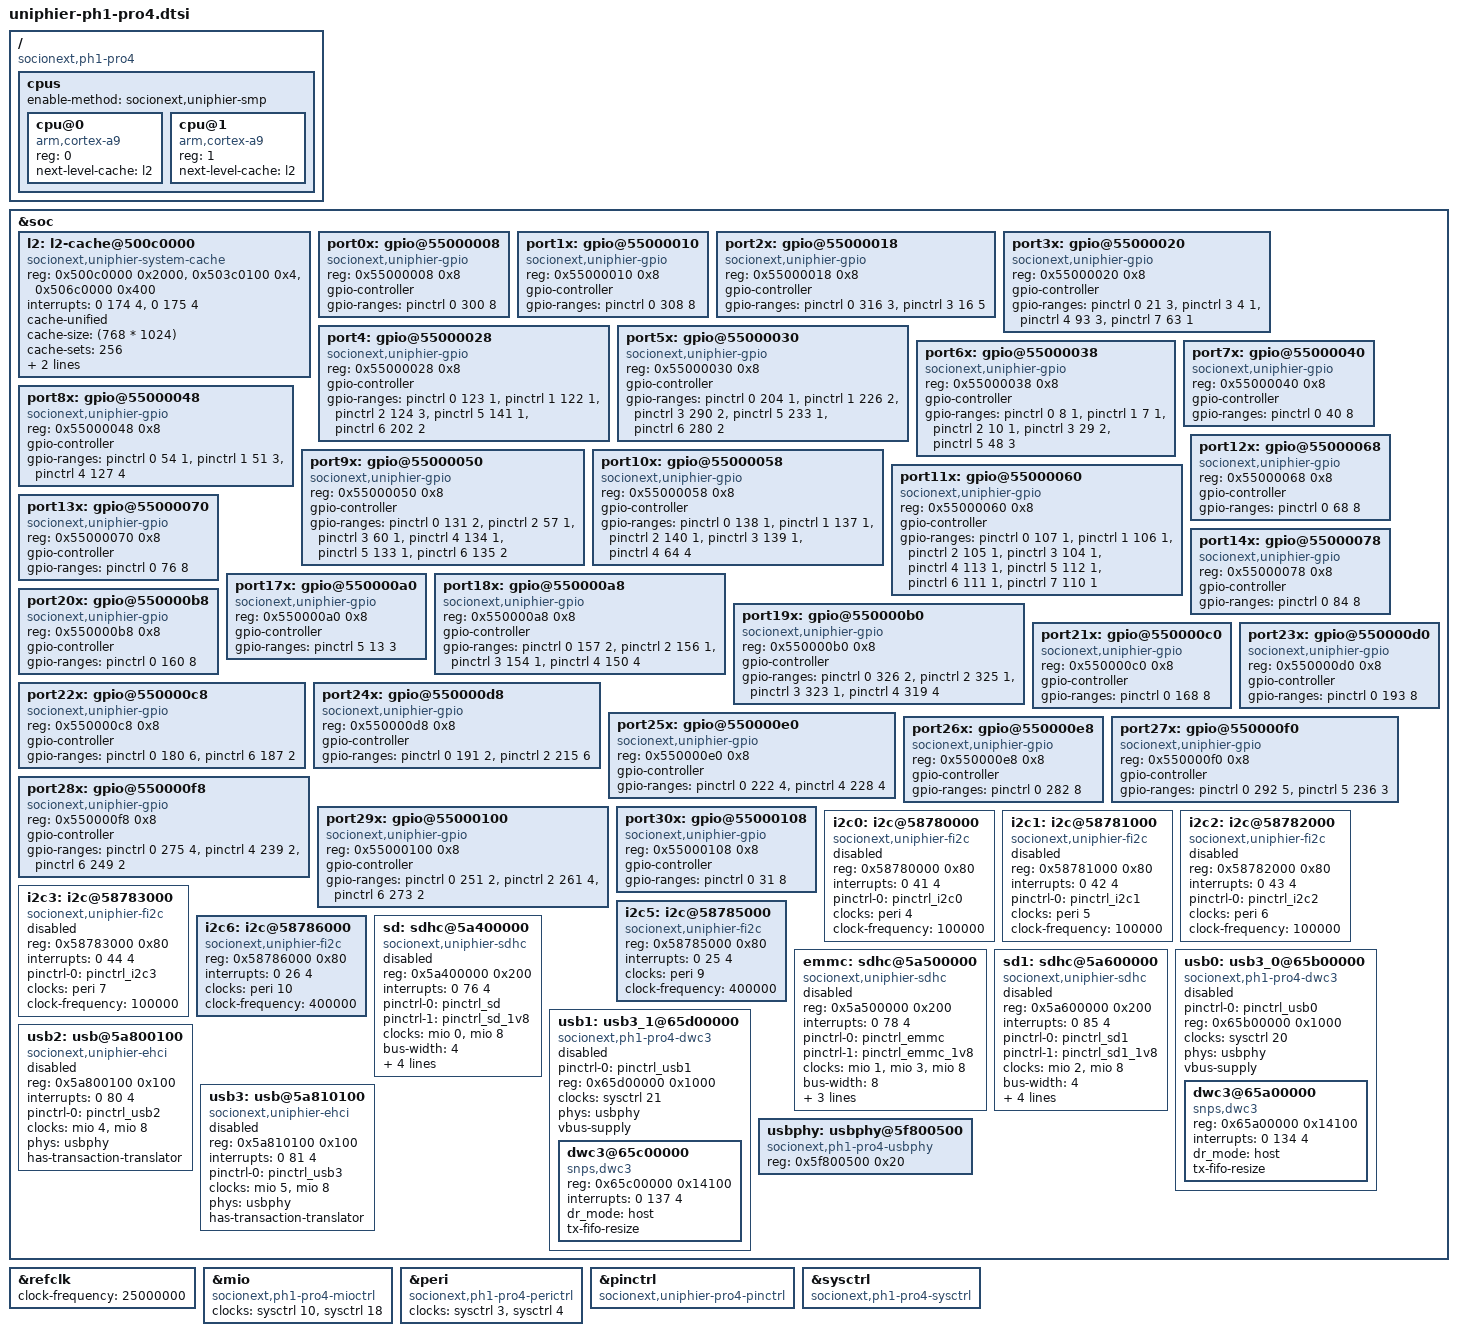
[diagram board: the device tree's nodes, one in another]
/*
 * Device Tree Source for UniPhier PH1-Pro4 SoC
 *
 * Copyright (C) 2015 Masahiro Yamada <yamada.masahiro@socionext.com>
 *
 * This file is dual-licensed: you can use it either under the terms
 * of the GPL or the X11 license, at your option. Note that this dual
 * licensing only applies to this file, and not this project as a
 * whole.
 *
 *  a) This file is free software; you can redistribute it and/or
 *     modify it under the terms of the GNU General Public License as
 *     published by the Free Software Foundation; either version 2 of the
 *     License, or (at your option) any later version.
 *
 *     This file is distributed in the hope that it will be useful,
 *     but WITHOUT ANY WARRANTY; without even the implied warranty of
 *     MERCHANTABILITY or FITNESS FOR A PARTICULAR PURPOSE.  See the
 *     GNU General Public License for more details.
 *
 * Or, alternatively,
 *
 *  b) Permission is hereby granted, free of charge, to any person
 *     obtaining a copy of this software and associated documentation
 *     files (the "Software"), to deal in the Software without
 *     restriction, including without limitation the rights to use,
 *     copy, modify, merge, publish, distribute, sublicense, and/or
 *     sell copies of the Software, and to permit persons to whom the
 *     Software is furnished to do so, subject to the following
 *     conditions:
 *
 *     The above copyright notice and this permission notice shall be
 *     included in all copies or substantial portions of the Software.
 *
 *     THE SOFTWARE IS PROVIDED "AS IS", WITHOUT WARRANTY OF ANY KIND,
 *     EXPRESS OR IMPLIED, INCLUDING BUT NOT LIMITED TO THE WARRANTIES
 *     OF MERCHANTABILITY, FITNESS FOR A PARTICULAR PURPOSE AND
 *     NONINFRINGEMENT. IN NO EVENT SHALL THE AUTHORS OR COPYRIGHT
 *     HOLDERS BE LIABLE FOR ANY CLAIM, DAMAGES OR OTHER LIABILITY,
 *     WHETHER IN AN ACTION OF CONTRACT, TORT OR OTHERWISE, ARISING
 *     FROM, OUT OF OR IN CONNECTION WITH THE SOFTWARE OR THE USE OR
 *     OTHER DEALINGS IN THE SOFTWARE.
 */

/include/ "uniphier-common32.dtsi"

/ {
	compatible = "socionext,ph1-pro4";

	cpus {
		#address-cells = <1>;
		#size-cells = <0>;
		enable-method = "socionext,uniphier-smp";

		cpu@0 {
			device_type = "cpu";
			compatible = "arm,cortex-a9";
			reg = <0>;
			next-level-cache = <&l2>;
		};

		cpu@1 {
			device_type = "cpu";
			compatible = "arm,cortex-a9";
			reg = <1>;
			next-level-cache = <&l2>;
		};
	};
};

&soc {
	l2: l2-cache@500c0000 {
		compatible = "socionext,uniphier-system-cache";
		reg = <0x500c0000 0x2000>, <0x503c0100 0x4>, <0x506c0000 0x400>;
		interrupts = <0 174 4>, <0 175 4>;
		cache-unified;
		cache-size = <(768 * 1024)>;
		cache-sets = <256>;
		cache-line-size = <128>;
		cache-level = <2>;
	};

	port0x: gpio@55000008 {
		compatible = "socionext,uniphier-gpio";
		reg = <0x55000008 0x8>;
		gpio-controller;
		#gpio-cells = <2>;
		gpio-ranges = <&pinctrl 0 300 8>;
	};

	port1x: gpio@55000010 {
		compatible = "socionext,uniphier-gpio";
		reg = <0x55000010 0x8>;
		gpio-controller;
		#gpio-cells = <2>;
		gpio-ranges = <&pinctrl 0 308 8>;
	};

	port2x: gpio@55000018 {
		compatible = "socionext,uniphier-gpio";
		reg = <0x55000018 0x8>;
		gpio-controller;
		#gpio-cells = <2>;
		gpio-ranges = <&pinctrl 0 316 3>,
			      <&pinctrl 3 16 5>;
	};

	port3x: gpio@55000020 {
		compatible = "socionext,uniphier-gpio";
		reg = <0x55000020 0x8>;
		gpio-controller;
		#gpio-cells = <2>;
		gpio-ranges = <&pinctrl 0 21 3>,
			      <&pinctrl 3 4 1>,
			      <&pinctrl 4 93 3>,
			      <&pinctrl 7 63 1>;
	};

	port4: gpio@55000028 {
		compatible = "socionext,uniphier-gpio";
		reg = <0x55000028 0x8>;
		gpio-controller;
		#gpio-cells = <2>;
		gpio-ranges = <&pinctrl 0 123 1>,
			      <&pinctrl 1 122 1>,
			      <&pinctrl 2 124 3>,
			      <&pinctrl 5 141 1>,
			      <&pinctrl 6 202 2>;
	};

	port5x: gpio@55000030 {
		compatible = "socionext,uniphier-gpio";
		reg = <0x55000030 0x8>;
		gpio-controller;
		#gpio-cells = <2>;
		gpio-ranges = <&pinctrl 0 204 1>,
			      <&pinctrl 1 226 2>,
			      <&pinctrl 3 290 2>,
			      <&pinctrl 5 233 1>,
			      <&pinctrl 6 280 2>;
	};

	port6x: gpio@55000038 {
		compatible = "socionext,uniphier-gpio";
		reg = <0x55000038 0x8>;
		gpio-controller;
		#gpio-cells = <2>;
		gpio-ranges = <&pinctrl 0 8 1>,
			      <&pinctrl 1 7 1>,
			      <&pinctrl 2 10 1>,
			      <&pinctrl 3 29 2>,
			      <&pinctrl 5 48 3>;
	};

	port7x: gpio@55000040 {
		compatible = "socionext,uniphier-gpio";
		reg = <0x55000040 0x8>;
		gpio-controller;
		#gpio-cells = <2>;
		gpio-ranges = <&pinctrl 0 40 8>;
	};

	port8x: gpio@55000048 {
		compatible = "socionext,uniphier-gpio";
		reg = <0x55000048 0x8>;
		gpio-controller;
		#gpio-cells = <2>;
		gpio-ranges = <&pinctrl 0 54 1>,
			      <&pinctrl 1 51 3>,
			      <&pinctrl 4 127 4>;
	};

	port9x: gpio@55000050 {
		compatible = "socionext,uniphier-gpio";
		reg = <0x55000050 0x8>;
		gpio-controller;
		#gpio-cells = <2>;
		gpio-ranges = <&pinctrl 0 131 2>,
			      <&pinctrl 2 57 1>,
			      <&pinctrl 3 60 1>,
			      <&pinctrl 4 134 1>,
			      <&pinctrl 5 133 1>,
			      <&pinctrl 6 135 2>;
	};

	port10x: gpio@55000058 {
		compatible = "socionext,uniphier-gpio";
		reg = <0x55000058 0x8>;
		gpio-controller;
		#gpio-cells = <2>;
		gpio-ranges = <&pinctrl 0 138 1>,
			      <&pinctrl 1 137 1>,
			      <&pinctrl 2 140 1>,
			      <&pinctrl 3 139 1>,
			      <&pinctrl 4 64 4>;
	};

	port11x: gpio@55000060 {
		compatible = "socionext,uniphier-gpio";
		reg = <0x55000060 0x8>;
		gpio-controller;
		#gpio-cells = <2>;
		gpio-ranges = <&pinctrl 0 107 1>,
			      <&pinctrl 1 106 1>,
			      <&pinctrl 2 105 1>,
			      <&pinctrl 3 104 1>,
			      <&pinctrl 4 113 1>,
			      <&pinctrl 5 112 1>,
			      <&pinctrl 6 111 1>,
			      <&pinctrl 7 110 1>;
	};

	port12x: gpio@55000068 {
		compatible = "socionext,uniphier-gpio";
		reg = <0x55000068 0x8>;
		gpio-controller;
		#gpio-cells = <2>;
		gpio-ranges = <&pinctrl 0 68 8>;
	};

	port13x: gpio@55000070 {
		compatible = "socionext,uniphier-gpio";
		reg = <0x55000070 0x8>;
		gpio-controller;
		#gpio-cells = <2>;
		gpio-ranges = <&pinctrl 0 76 8>;
	};

	port14x: gpio@55000078 {
		compatible = "socionext,uniphier-gpio";
		reg = <0x55000078 0x8>;
		gpio-controller;
		#gpio-cells = <2>;
		gpio-ranges = <&pinctrl 0 84 8>;
	};

	port17x: gpio@550000a0 {
		compatible = "socionext,uniphier-gpio";
		reg = <0x550000a0 0x8>;
		gpio-controller;
		#gpio-cells = <2>;
		gpio-ranges = <&pinctrl 5 13 3>;
	};

	port18x: gpio@550000a8 {
		compatible = "socionext,uniphier-gpio";
		reg = <0x550000a8 0x8>;
		gpio-controller;
		#gpio-cells = <2>;
		gpio-ranges = <&pinctrl 0 157 2>,
			      <&pinctrl 2 156 1>,
			      <&pinctrl 3 154 1>,
			      <&pinctrl 4 150 4>;
	};

	port19x: gpio@550000b0 {
		compatible = "socionext,uniphier-gpio";
		reg = <0x550000b0 0x8>;
		gpio-controller;
		#gpio-cells = <2>;
		gpio-ranges = <&pinctrl 0 326 2>,
			      <&pinctrl 2 325 1>,
			      <&pinctrl 3 323 1>,
			      <&pinctrl 4 319 4>;
	};

	port20x: gpio@550000b8 {
		compatible = "socionext,uniphier-gpio";
		reg = <0x550000b8 0x8>;
		gpio-controller;
		#gpio-cells = <2>;
		gpio-ranges = <&pinctrl 0 160 8>;
	};

	port21x: gpio@550000c0 {
		compatible = "socionext,uniphier-gpio";
		reg = <0x550000c0 0x8>;
		gpio-controller;
		#gpio-cells = <2>;
		gpio-ranges = <&pinctrl 0 168 8>;
	};

	port22x: gpio@550000c8 {
		compatible = "socionext,uniphier-gpio";
		reg = <0x550000c8 0x8>;
		gpio-controller;
		#gpio-cells = <2>;
		gpio-ranges = <&pinctrl 0 180 6>,
			      <&pinctrl 6 187 2>;
	};

	port23x: gpio@550000d0 {
		compatible = "socionext,uniphier-gpio";
		reg = <0x550000d0 0x8>;
		gpio-controller;
		#gpio-cells = <2>;
		gpio-ranges = <&pinctrl 0 193 8>;
	};

	port24x: gpio@550000d8 {
		compatible = "socionext,uniphier-gpio";
		reg = <0x550000d8 0x8>;
		gpio-controller;
		#gpio-cells = <2>;
		gpio-ranges = <&pinctrl 0 191 2>,
			      <&pinctrl 2 215 6>;
	};

	port25x: gpio@550000e0 {
		compatible = "socionext,uniphier-gpio";
		reg = <0x550000e0 0x8>;
		gpio-controller;
		#gpio-cells = <2>;
		gpio-ranges = <&pinctrl 0 222 4>,
			      <&pinctrl 4 228 4>;
	};

	port26x: gpio@550000e8 {
		compatible = "socionext,uniphier-gpio";
		reg = <0x550000e8 0x8>;
		gpio-controller;
		#gpio-cells = <2>;
		gpio-ranges = <&pinctrl 0 282 8>;
	};

	port27x: gpio@550000f0 {
		compatible = "socionext,uniphier-gpio";
		reg = <0x550000f0 0x8>;
		gpio-controller;
		#gpio-cells = <2>;
		gpio-ranges = <&pinctrl 0 292 5>,
			      <&pinctrl 5 236 3>;
	};

	port28x: gpio@550000f8 {
		compatible = "socionext,uniphier-gpio";
		reg = <0x550000f8 0x8>;
		gpio-controller;
		#gpio-cells = <2>;
		gpio-ranges = <&pinctrl 0 275 4>,
			      <&pinctrl 4 239 2>,
			      <&pinctrl 6 249 2>;
	};

	port29x: gpio@55000100 {
		compatible = "socionext,uniphier-gpio";
		reg = <0x55000100 0x8>;
		gpio-controller;
		#gpio-cells = <2>;
		gpio-ranges = <&pinctrl 0 251 2>,
			      <&pinctrl 2 261 4>,
			      <&pinctrl 6 273 2>;
	};

	port30x: gpio@55000108 {
		compatible = "socionext,uniphier-gpio";
		reg = <0x55000108 0x8>;
		gpio-controller;
		#gpio-cells = <2>;
		gpio-ranges = <&pinctrl 0 31 8>;
	};

	i2c0: i2c@58780000 {
		compatible = "socionext,uniphier-fi2c";
		status = "disabled";
		reg = <0x58780000 0x80>;
		#address-cells = <1>;
		#size-cells = <0>;
		interrupts = <0 41 4>;
		pinctrl-names = "default";
		pinctrl-0 = <&pinctrl_i2c0>;
		clocks = <&peri 4>;
		clock-frequency = <100000>;
	};

	i2c1: i2c@58781000 {
		compatible = "socionext,uniphier-fi2c";
		status = "disabled";
		reg = <0x58781000 0x80>;
		#address-cells = <1>;
		#size-cells = <0>;
		interrupts = <0 42 4>;
		pinctrl-names = "default";
		pinctrl-0 = <&pinctrl_i2c1>;
		clocks = <&peri 5>;
		clock-frequency = <100000>;
	};

	i2c2: i2c@58782000 {
		compatible = "socionext,uniphier-fi2c";
		status = "disabled";
		reg = <0x58782000 0x80>;
		#address-cells = <1>;
		#size-cells = <0>;
		interrupts = <0 43 4>;
		pinctrl-names = "default";
		pinctrl-0 = <&pinctrl_i2c2>;
		clocks = <&peri 6>;
		clock-frequency = <100000>;
	};

	i2c3: i2c@58783000 {
		compatible = "socionext,uniphier-fi2c";
		status = "disabled";
		reg = <0x58783000 0x80>;
		#address-cells = <1>;
		#size-cells = <0>;
		interrupts = <0 44 4>;
		pinctrl-names = "default";
		pinctrl-0 = <&pinctrl_i2c3>;
		clocks = <&peri 7>;
		clock-frequency = <100000>;
	};

	/* i2c4 does not exist */

	/* chip-internal connection for DMD */
	i2c5: i2c@58785000 {
		compatible = "socionext,uniphier-fi2c";
		reg = <0x58785000 0x80>;
		#address-cells = <1>;
		#size-cells = <0>;
		interrupts = <0 25 4>;
		clocks = <&peri 9>;
		clock-frequency = <400000>;
	};

	/* chip-internal connection for HDMI */
	i2c6: i2c@58786000 {
		compatible = "socionext,uniphier-fi2c";
		reg = <0x58786000 0x80>;
		#address-cells = <1>;
		#size-cells = <0>;
		interrupts = <0 26 4>;
		clocks = <&peri 10>;
		clock-frequency = <400000>;
	};

	sd: sdhc@5a400000 {
		compatible = "socionext,uniphier-sdhc";
		status = "disabled";
		reg = <0x5a400000 0x200>;
		interrupts = <0 76 4>;
		pinctrl-names = "default", "1.8v";
		pinctrl-0 = <&pinctrl_sd>;
		pinctrl-1 = <&pinctrl_sd_1v8>;
		clock-names = "host", "dmac";
		clocks = <&mio 0>, <&mio 8>;
		bus-width = <4>;
		cap-sd-highspeed;
		sd-uhs-sdr12;
		sd-uhs-sdr25;
		sd-uhs-sdr50;
	};

	emmc: sdhc@5a500000 {
		compatible = "socionext,uniphier-sdhc";
		status = "disabled";
		reg = <0x5a500000 0x200>;
		interrupts = <0 78 4>;
		pinctrl-names = "default", "1.8v";
		pinctrl-0 = <&pinctrl_emmc>;
		pinctrl-1 = <&pinctrl_emmc_1v8>;
		clock-names = "host", "hw-reset", "dmac";
		clocks = <&mio 1>, <&mio 3>, <&mio 8>;
		bus-width = <8>;
		non-removable;
		cap-mmc-highspeed;
		cap-mmc-hw-reset;
	};

	sd1: sdhc@5a600000 {
		compatible = "socionext,uniphier-sdhc";
		status = "disabled";
		reg = <0x5a600000 0x200>;
		interrupts = <0 85 4>;
		pinctrl-names = "default", "1.8v";
		pinctrl-0 = <&pinctrl_sd1>;
		pinctrl-1 = <&pinctrl_sd1_1v8>;
		clock-names = "host", "dmac";
		clocks = <&mio 2>, <&mio 8>;
		bus-width = <4>;
		cap-sd-highspeed;
		sd-uhs-sdr12;
		sd-uhs-sdr25;
		sd-uhs-sdr50;
	};

	usb0: usb3_0@65b00000 {
		compatible = "socionext,ph1-pro4-dwc3";
		status = "disabled";
		pinctrl-names = "default";
		pinctrl-0 = <&pinctrl_usb0>;
		reg = <0x65b00000 0x1000>;
		clocks = <&sysctrl 20>;
		clock-names = "u3clk0";
		phys = <&usbphy>;
		phy-names = "usb";
		#address-cells = <1>;
		#size-cells = <1>;
		vbus-supply;
		ranges;
		dwc3@65a00000 {
			compatible = "snps,dwc3";
			reg = <0x65a00000 0x14100>;
			interrupts = <0 134 4>;
			dr_mode = "host";
			tx-fifo-resize;
		};
	};

	usb1: usb3_1@65d00000 {
		compatible = "socionext,ph1-pro4-dwc3";
		status = "disabled";
		pinctrl-names = "default";
		pinctrl-0 = <&pinctrl_usb1>;
		reg = <0x65d00000 0x1000>;
		clocks = <&sysctrl 21>;
		clock-names = "u3clk0";
		phys = <&usbphy>;
		phy-names = "usb";
		#address-cells = <1>;
		#size-cells = <1>;
		vbus-supply;
		ranges;
		dwc3@65c00000 {
			compatible = "snps,dwc3";
			reg = <0x65c00000 0x14100>;
			interrupts = <0 137 4>;
			dr_mode = "host";
			tx-fifo-resize;
		};

	};

	usb2: usb@5a800100 {
		compatible = "socionext,uniphier-ehci", "generic-ehci";
		status = "disabled";
		reg = <0x5a800100 0x100>;
		interrupts = <0 80 4>;
		pinctrl-names = "default";
		pinctrl-0 = <&pinctrl_usb2>;
		clocks = <&mio 4>, <&mio 8>;
		phys = <&usbphy>;
		phy-names = "usb";
		has-transaction-translator;
	};

	usb3: usb@5a810100 {
		compatible = "socionext,uniphier-ehci", "generic-ehci";
		status = "disabled";
		reg = <0x5a810100 0x100>;
		interrupts = <0 81 4>;
		pinctrl-names = "default";
		pinctrl-0 = <&pinctrl_usb3>;
		clocks = <&mio 5>, <&mio 8>;
		phys = <&usbphy>;
		phy-names = "usb";
		has-transaction-translator;
	};

	usbphy: usbphy@5f800500 {
		#phy-cells = <0>;
		compatible = "socionext,ph1-pro4-usbphy";
		reg = <0x5f800500 0x20>;
	};
};

&refclk {
	clock-frequency = <25000000>;
};

&mio {
	compatible = "socionext,ph1-pro4-mioctrl";
	clock-names = "stdmac", "ehci";
	clocks = <&sysctrl 10>, <&sysctrl 18>;
};

&peri {
	compatible = "socionext,ph1-pro4-perictrl";
	clock-names = "uart", "fi2c";
	clocks = <&sysctrl 3>, <&sysctrl 4>;
};

&pinctrl {
	compatible = "socionext,uniphier-pro4-pinctrl";
};

&sysctrl {
	compatible = "socionext,ph1-pro4-sysctrl";
};
